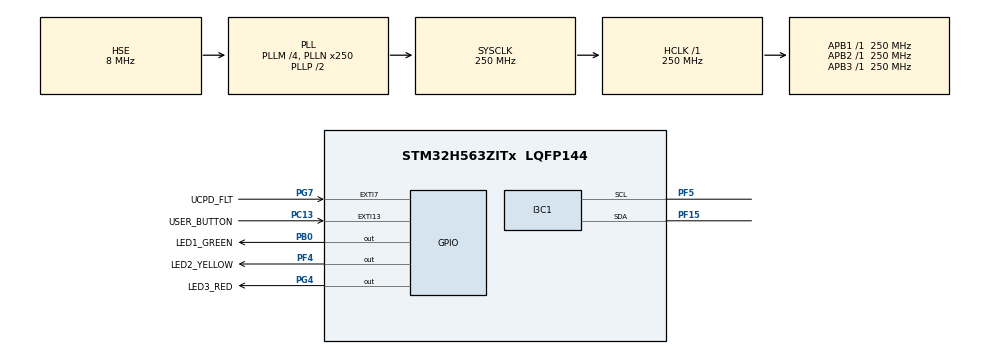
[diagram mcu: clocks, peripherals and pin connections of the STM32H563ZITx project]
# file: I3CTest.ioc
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CORTEX_M33_NS.userName=CORTEX_M33
I3C1.BusFreeDuration=1050
I3C1.BusUsage=MixedUsage
I3C1.DutyCycleI3C=50
I3C1.Register0=0x4aae0909
I3C1.Register1=0x108300f8
I3C1.SCLI2CHighDuration=0x4a
I3C1.SCLI3CHighDuration=0x09
I3C1.SCLODLowDuration=0xae
I3C1.SCLPPLowDuration=0x09
I3C1.SDAHoldTime=HAL_I3C_SDA_HOLD_TIME_1_5
I3C1.hexBusFreeDuration=0x83
I3C1.hexBusIdleDuration=0xf8
Mcu.Family=STM32H5
Mcu.Name=STM32H563ZITx
Mcu.Package=LQFP144
NVIC.PriorityGroup=NVIC_PRIORITYGROUP_4
PA1.GPIO_Label=RMII_REF_CLK
PA1.GPIO_Mode=GPIO_MODE_AF_PP
PA1.GPIO_PuPd=GPIO_NOPULL
PA1.GPIO_Speed=GPIO_SPEED_FREQ_LOW
PA1.Signal=ETH_REF_CLK
PA11.GPIO_Label=USB_FS_N
PA11.Signal=USB_DM
PA12.GPIO_Label=USB_FS_P
PA12.Signal=USB_DP
PA13(JTMS/SWDIO).GPIO_Label=SWDIO
PA13(JTMS/SWDIO).Signal=DEBUG_JTMS-SWDIO
PA14(JTCK/SWCLK).GPIO_Label=SWCLK
PA14(JTCK/SWCLK).Signal=DEBUG_JTCK-SWCLK
PA15(JTDI).GPIO_Label=T_JTDI
PA15(JTDI).Signal=DEBUG_JTDI
PA2.GPIO_Label=RMII_MDIO
PA2.GPIO_Mode=GPIO_MODE_AF_PP
PA2.GPIO_PuPd=GPIO_NOPULL
PA2.GPIO_Speed=GPIO_SPEED_FREQ_LOW
PA2.Signal=ETH_MDIO
PA4.GPIO_Label=VBUS_SENSE
PA4.Signal=ADCx_INP18
PA7.GPIO_Label=RMII_CRS_DV
PA7.GPIO_Mode=GPIO_MODE_AF_PP
PA7.GPIO_PuPd=GPIO_NOPULL
PA7.GPIO_Speed=GPIO_SPEED_FREQ_LOW
PA7.Signal=ETH_CRS_DV
PA9.GPIO_Label=UCDP_DBn
PA9.Signal=UCPD1_DB1
PB0.GPIO_Label=LED1_GREEN
PB0.Signal=GPIO_Output
PB13.GPIO_Label=UCPD_CC1
PB13.Signal=UCPD1_CC1
PB14.GPIO_Label=UCPD_CC2
PB14.Signal=UCPD1_CC2
PB15.GPIO_Label=RMII_TXD1
PB15.GPIO_Mode=GPIO_MODE_AF_PP
PB15.GPIO_PuPd=GPIO_NOPULL
PB15.GPIO_Speed=GPIO_SPEED_FREQ_LOW
PB15.Signal=ETH_TXD1
PB3(JTDO/TRACESWO).GPIO_Label=SWO
PB3(JTDO/TRACESWO).Signal=DEBUG_JTDO-SWO
PB6.GPIO_Label=ARD_D1_TX
PB6.Signal=LPUART1_TX
PB7.GPIO_Label=ARD_D0_RX
PB7.Signal=LPUART1_RX
PC1.GPIO_Label=RMII_MDC
PC1.GPIO_Mode=GPIO_MODE_AF_PP
PC1.GPIO_PuPd=GPIO_NOPULL
PC1.GPIO_Speed=GPIO_SPEED_FREQ_LOW
PC1.Signal=ETH_MDC
PC13.GPIO_Label=USER_BUTTON
PC13.Signal=GPXTI13
PC14-OSC32_IN(OSC32_IN).Mode=LSE-External-Oscillator
PC14-OSC32_IN(OSC32_IN).Signal=RCC_OSC32_IN
PC15-OSC32_OUT(OSC32_OUT).Mode=LSE-External-Oscillator
PC15-OSC32_OUT(OSC32_OUT).Signal=RCC_OSC32_OUT
PC4.GPIO_Label=RMII_RXD0
PC4.GPIO_Mode=GPIO_MODE_AF_PP
PC4.GPIO_PuPd=GPIO_NOPULL
PC4.GPIO_Speed=GPIO_SPEED_FREQ_LOW
PC4.Signal=ETH_RXD0
PC5.GPIO_Label=RMII_RXD1
PC5.GPIO_Mode=GPIO_MODE_AF_PP
PC5.GPIO_PuPd=GPIO_NOPULL
PC5.GPIO_Speed=GPIO_SPEED_FREQ_LOW
PC5.Signal=ETH_RXD1
PD8.GPIO_Label=T_VCP_TX
PD8.Signal=USART3_TX
PD9.GPIO_Label=T_VCP_RX
PD9.Signal=USART3_RX
PE2.GPIO_Label=TRACE_CK
PE2.Signal=DEBUG_TRACECLK
PE3.GPIO_Label=TRACE_D0
PE3.Signal=DEBUG_TRACED0
PE4.GPIO_Label=TRACE_D1
PE4.Signal=DEBUG_TRACED1
PE5.GPIO_Label=TRACE_D2
PE5.Signal=DEBUG_TRACED2
PE6.GPIO_Label=TRACE_D3
PE6.Signal=DEBUG_TRACED3
PF15.Mode=Controller
PF15.Signal=I3C1_SDA
PF4.GPIO_Label=LED2_YELLOW
PF4.Signal=GPIO_Output
PF5.Mode=Controller
PF5.Signal=I3C1_SCL
PG11.GPIO_Label=RMII_TXT_EN
PG11.GPIO_Mode=GPIO_MODE_AF_PP
PG11.GPIO_PuPd=GPIO_NOPULL
PG11.GPIO_Speed=GPIO_SPEED_FREQ_LOW
PG11.Signal=ETH_TX_EN
PG13.GPIO_Label=RMI_TXD0
PG13.GPIO_Mode=GPIO_MODE_AF_PP
PG13.GPIO_PuPd=GPIO_NOPULL
PG13.GPIO_Speed=GPIO_SPEED_FREQ_LOW
PG13.Signal=ETH_TXD0
PG4.GPIO_Label=LED3_RED
PG4.Signal=GPIO_Output
PG7.GPIO_Label=UCPD_FLT
PG7.Signal=GPXTI7
PH0-OSC_IN(PH0).GPIO_Label=STLK_MCO
PH0-OSC_IN(PH0).Mode=HSE-DIG-External-Clock-Source
PH0-OSC_IN(PH0).Signal=RCC_OSC_IN
ProjectManager.HeapSize=0x200
ProjectManager.StackSize=0x400
ProjectManager.TargetToolchain=STM32CubeIDE
RCC.ADCFreq_Value=250000000
RCC.AHBFreq_Value=250000000
RCC.APB1Freq_Value=250000000
RCC.APB1TimFreq_Value=250000000
RCC.APB2Freq_Value=250000000
RCC.APB2TimFreq_Value=250000000
RCC.APB3Freq_Value=250000000
RCC.CSI_VALUE=4000000
RCC.CortexFreq_Value=250000000
RCC.EPOD_VALUE=8000000
RCC.HCLKFreq_Value=250000000
RCC.HSE_VALUE=8000000
RCC.HSI48_VALUE=48000000
RCC.HSIDiv=RCC_HSI_DIV1
RCC.HSI_VALUE=64000000
RCC.LSIRC_VALUE=32000
RCC.PLLM=4
RCC.PLLN=250
RCC.PLLSourceVirtual=RCC_PLL1_SOURCE_HSE
RCC.SYSCLKFreq_VALUE=250000000
RCC.SYSCLKSource=RCC_SYSCLKSOURCE_PLLCLK
RCC.USBFreq_Value=48000000
RCC.VCOOutputFreq_Value=500000000
SH.ADCx_INP18.0=ADC1_INP18
VP_ICACHE_VS_ICACHE.Mode=DirectMappedCache
VP_PWR_VS_SECSignals.Mode=Security/Privilege
board=NUCLEO-H563ZI

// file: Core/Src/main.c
/* USER CODE BEGIN Header */
/**
 ******************************************************************************
 * @file           : main.c
 * @brief          : Main program body
 ******************************************************************************
 * @attention
 *
 * Copyright (c) 2023 STMicroelectronics.
 * All rights reserved.
 *
 * This software is licensed under terms that can be found in the LICENSE file
 * in the root directory of this software component.
 * If no LICENSE file comes with this software, it is provided AS-IS.
 *
 ******************************************************************************
 */
/* USER CODE END Header */
#include "main.h"

/* USER CODE BEGIN Includes */
#include "bmi3.h"
#include "bmi323.h"
#include "common.h"
#include <stdio.h>
#include <math.h>
#include "i3c_handle.h"

/* USER CODE END Includes */

/* USER CODE BEGIN PD */
/*! Earth's gravity in m/s^2 */
#define GRAVITY_EARTH (9.80665f)

#define ACCEL UINT8_C(0x00)
#define GYRO UINT8_C(0x01)
#define TEMPERATURE UINT8_C(0x02)
/* USER CODE END PD */

I3C_HandleTypeDef hi3c1;

/* USER CODE BEGIN PV */
/******************************************************************************/
/*!         Structure Definition                                              */

/*! Structure to define accelerometer and gyroscope configuration. */
struct bmi3_sens_config config[2];

/******************************************************************************/
/*!         Static Function Declaration                                       */

/*!
 *  @brief This internal API is used to set configurations for FIFO, accelerometer and gyroscope.
 *
 *  @param[in] dev       : Structure instance of bmi3_dev.
 *
 *  @return Status of execution.
 */
static int8_t set_sensor_config(struct bmi3_dev *dev);

/*!
 *  @brief This internal function converts lsb to meter per second squared for 16 bit accelerometer for
 *  range 2G, 4G, 8G or 16G.
 *
 *  @param[in] val       : LSB from each axis.
 *  @param[in] g_range   : Gravity range.
 *  @param[in] bit_width : Resolution for accel.
 *
 *  @return Accel values in meter per second squared.
 */
static float lsb_to_mps2(int16_t val, int8_t g_range, uint8_t bit_width);

/*!
 *  @brief This function converts lsb to degree per second for 16 bit gyro at
 *  range 125, 250, 500, 1000 or 2000dps.
 *
 *  @param[in] val       : LSB from each axis.
 *  @param[in] dps       : Degree per second.
 *  @param[in] bit_width : Resolution for gyro.
 *
 *  @return Degree per second.
 */
static float lsb_to_dps(int16_t val, float dps, uint8_t bit_width);
/* USER CODE END PV */

void SystemClock_Config(void);
static void MX_GPIO_Init(void);
static void MX_I3C1_Init(void);
static void MX_ICACHE_Init(void);

int main(void)
{

  /* MCU Configuration--------------------------------------------------------*/

  /* Reset of all peripherals, Initializes the Flash interface and the Systick. */
  HAL_Init();

  /* Configure the system clock */
  SystemClock_Config();

  /* Initialize all configured peripherals */
  MX_GPIO_Init();
  MX_I3C1_Init();
  MX_ICACHE_Init();

  /* Infinite loop */
  /* USER CODE BEGIN WHILE */
  struct bmi3_dev dev;
  int8_t rslt;

  /* Variable to set the data sample rate of i3c sync
   * 0x0032 is set to 50 samples this value can vary  */
  uint16_t sample_rate = 0x0032;

  /* Variable to set the delay time of i3c sync */
  uint8_t delay_time = BMI3_I3C_SYNC_DIVISION_FACTOR_11;

  /* Variable to set the i3c sync ODR */
  uint8_t odr = BMI3_I3C_SYNC_ODR_50HZ;

  /* Variable to enable the filer */
  uint8_t i3c_tc_res = BMI323_ENABLE;

  uint8_t limit = 20;

  uint16_t int_status;

  struct bmi3_feature_enable feature = {0};

  struct bmi3_sensor_data sensor_data[3];

  /* Variable to store temperature */
  float temperature_value;

  float acc_x = 0, acc_y = 0, acc_z = 0;
  float gyr_x = 0, gyr_y = 0, gyr_z = 0;
  uint8_t indx = 0;

  /* Function to select interface between SPI and I2C, according to that the device structure gets updated.
   * Interface reference is given as a parameter
   * For I2C : BMI3_I2C_INTF
   * For SPI : BMI3_SPI_INTF
   */
  rslt = bmi3_interface_init(&dev, BMI3_I3C_INTF);
  bmi3_error_codes_print_result("bmi3_interface_init", rslt);

  if (rslt == BMI323_OK)
  {
    /* Initialize BMI323 */
    rslt = bmi323_init(&dev);
    bmi3_error_codes_print_result("bmi323_init", rslt);

    if (rslt == BMI323_OK)
    {
      rslt = bmi323_configure_enhanced_flexibility(&dev);
      bmi3_error_codes_print_result("bmi323_configure_enhanced_flexibility", rslt);

      if (rslt == BMI323_OK)
      {
        rslt = set_sensor_config(&dev);
        bmi3_error_codes_print_result("set_sensor_config", rslt);

        /* Enable i3c_sync feature */
        feature.i3c_sync_en = BMI323_ENABLE;

        /* Enable the selected sensors */
        rslt = bmi323_select_sensor(&feature, &dev);
        bmi3_error_codes_print_result("bmi323_select_sensor", rslt);

        /* Set the data sample rate of i3c sync */
        rslt = bmi323_set_i3c_tc_sync_tph(sample_rate, &dev);
        bmi3_error_codes_print_result("set_i3c_tc_sync_tph", rslt);

        /* Set the delay time of i3c sync */
        rslt = bmi323_set_i3c_tc_sync_tu(delay_time, &dev);
        bmi3_error_codes_print_result("set_i3c_tc_sync_tu", rslt);

        /* Set i3c sync ODR */
        rslt = bmi323_set_i3c_tc_sync_odr(odr, &dev);
        bmi3_error_codes_print_result("set_i3c_tc_sync_odr", rslt);

        /* Enable the i3c sync filter */
        rslt = bmi323_set_i3c_sync_i3c_tc_res(i3c_tc_res, &dev);
        bmi3_error_codes_print_result("set_i3c_sync_i3c_tc_res", rslt);

        /* After any change to the I3C-Sync configuration parameters,
         * a config changed CMD (0x0201) must be written
         * to CMD register to update the internal configuration */
        rslt = bmi323_set_command_register(BMI3_CMD_I3C_TCSYNC_UPDATE, &dev);
        bmi3_error_codes_print_result("bmi323_set_command_register", rslt);

        /* Set the type of sensor data */
        sensor_data[ACCEL].type = BMI3_I3C_SYNC_ACCEL;
        sensor_data[GYRO].type = BMI3_I3C_SYNC_GYRO;
        sensor_data[TEMPERATURE].type = BMI3_I3C_SYNC_TEMP;

        printf("I3C accel, gyro and temperature data\n");

        printf(
            "\nDATA_SET, i3c_acc_x, i3c_acc_y, i3c_acc_z, i3c_time, Gravity-x, Gravity-y, Gravity-z, i3c_gyro_x, i3c_gyro_y, i3c_gyro_z, DPS-x, DPS-y, DPS-z, i3c_temperature, i3c_sync_time, Temperature data(Degree Celcius)\n");

        while (indx <= limit)
        {
          /* Delay provided based on i3c sync ODR */
          dev.delay_us(20000, dev.intf_ptr);

          /* To get the status of i3c sync interrupt status. */
          rslt = bmi323_get_int1_status(&int_status, &dev);
          bmi3_error_codes_print_result("bmi323_get_int1_status", rslt);

          /* To check the i3c sync accel data */
          if (int_status & BMI3_INT_STATUS_I3C)
          {
            rslt = bmi323_get_sensor_data(sensor_data, 3, &dev);
            bmi3_error_codes_print_result("bmi323_get_sensor_data", rslt);

            /* Converting lsb to meter per second squared for 16 bit accelerometer at 2G range. */
            acc_x = lsb_to_mps2((int16_t)sensor_data[ACCEL].sens_data.i3c_sync.sync_x, 2, dev.resolution);
            acc_y = lsb_to_mps2((int16_t)sensor_data[ACCEL].sens_data.i3c_sync.sync_y, 2, dev.resolution);
            acc_z = lsb_to_mps2((int16_t)sensor_data[ACCEL].sens_data.i3c_sync.sync_z, 2, dev.resolution);

            /* Converting lsb to degree per second for 16 bit gyro at 2000dps range. */
            gyr_x = lsb_to_dps((int16_t)sensor_data[GYRO].sens_data.i3c_sync.sync_x,
                               (float)2000,
                               dev.resolution);
            gyr_y = lsb_to_dps((int16_t)sensor_data[GYRO].sens_data.i3c_sync.sync_y,
                               (float)2000,
                               dev.resolution);
            gyr_z = lsb_to_dps((int16_t)sensor_data[GYRO].sens_data.i3c_sync.sync_z,
                               (float)2000,
                               dev.resolution);

            temperature_value =
                (float)((((float)((int16_t)sensor_data[TEMPERATURE].sens_data.i3c_sync.sync_temp)) /
                         512.0) +
                        23.0);

            printf(
                "%d, %d, %d, %d, %d, %4.2f, %4.2f, %4.2f, %d, %d, %d, %d, %4.2f, %4.2f, %4.2f, %d, %d, %f\t\n",
                indx,
                sensor_data[ACCEL].sens_data.i3c_sync.sync_x,
                sensor_data[ACCEL].sens_data.i3c_sync.sync_y,
                sensor_data[ACCEL].sens_data.i3c_sync.sync_z,
                sensor_data[ACCEL].sens_data.i3c_sync.sync_time,
                acc_x,
                acc_y,
                acc_z,
                sensor_data[GYRO].sens_data.i3c_sync.sync_x,
                sensor_data[GYRO].sens_data.i3c_sync.sync_y,
                sensor_data[GYRO].sens_data.i3c_sync.sync_z,
                sensor_data[GYRO].sens_data.i3c_sync.sync_time,
                gyr_x,
                gyr_y,
                gyr_z,
                sensor_data[TEMPERATURE].sens_data.i3c_sync.sync_temp,
                sensor_data[TEMPERATURE].sens_data.i3c_sync.sync_time,
                temperature_value);
          }

          indx++;
        }
      }
    }
  }

  // bmi3_coines_deinit();

  return rslt;
}

/*!
 * @brief This internal API is used to set configurations for accelerometer, gyroscope and FIFO.
 */
static int8_t set_sensor_config(struct bmi3_dev *dev)
{
  int8_t rslt;

  /* Structure to define interrupt with its feature */
  struct bmi3_map_int map_int = {0};

  /* Configure type of feature */
  config[ACCEL].type = BMI323_ACCEL;
  config[GYRO].type = BMI323_GYRO;

  /* Get default configurations for the type of feature selected */
  rslt = bmi323_get_sensor_config(config, 2, dev);
  bmi3_error_codes_print_result("bmi323_get_sensor_config", rslt);

  /* Configure the accel and gyro settings */
  config[ACCEL].cfg.acc.bwp = BMI3_ACC_BW_ODR_QUARTER;
  config[ACCEL].cfg.acc.range = BMI3_ACC_RANGE_2G;
  config[ACCEL].cfg.acc.acc_mode = BMI3_ACC_MODE_NORMAL;

  config[GYRO].cfg.gyr.bwp = BMI3_GYR_BW_ODR_HALF;
  config[GYRO].cfg.gyr.range = BMI3_GYR_RANGE_125DPS;
  config[GYRO].cfg.gyr.gyr_mode = BMI3_GYR_MODE_NORMAL;

  rslt = bmi323_set_sensor_config(config, 2, dev);
  bmi3_error_codes_print_result("bmi323_set_sensor_config", rslt);

  /* Get configurations for the type of feature selected */
  rslt = bmi323_get_sensor_config(config, 2, dev);
  bmi3_error_codes_print_result("bmi323_get_sensor_config", rslt);

  /* Select the feature and map the interrupt to pin BMI3_INT1 or BMI3_INT2 */
  map_int.i3c_out = BMI3_INT1;

  /* Map i3c sync interrupt to interrupt pin. */
  rslt = bmi323_map_interrupt(map_int, dev);
  bmi3_error_codes_print_result("bmi323_map_interrupt", rslt);

  return rslt;
}

/*!
 * @brief This function converts lsb to meter per second squared for 16 bit accelerometer at
 * range 2G, 4G, 8G or 16G.
 */
static float lsb_to_mps2(int16_t val, int8_t g_range, uint8_t bit_width)
{
  double power = 2;

  float half_scale = (float)((pow((double)power, (double)bit_width) / 2.0f));

  return (GRAVITY_EARTH * val * g_range) / half_scale;
}

/*!
 * @brief This function converts lsb to degree per second for 16 bit gyro at
 * range 125, 250, 500, 1000 or 2000dps.
 */
static float lsb_to_dps(int16_t val, float dps, uint8_t bit_width)
{
  double power = 2;

  float half_scale = (float)((pow((double)power, (double)bit_width) / 2.0f));

  return (dps / (half_scale)) * (val);
}

void SystemClock_Config(void)
{
  RCC_OscInitTypeDef RCC_OscInitStruct = {0};
  RCC_ClkInitTypeDef RCC_ClkInitStruct = {0};

  /** Configure the main internal regulator output voltage
   */
  __HAL_PWR_VOLTAGESCALING_CONFIG(PWR_REGULATOR_VOLTAGE_SCALE0);

  while (!__HAL_PWR_GET_FLAG(PWR_FLAG_VOSRDY))
  {
  }

  /** Initializes the RCC Oscillators according to the specified parameters
   * in the RCC_OscInitTypeDef structure.
   */
  RCC_OscInitStruct.OscillatorType = RCC_OSCILLATORTYPE_HSE;
  RCC_OscInitStruct.HSEState = RCC_HSE_BYPASS_DIGITAL;
  RCC_OscInitStruct.PLL.PLLState = RCC_PLL_ON;
  RCC_OscInitStruct.PLL.PLLSource = RCC_PLL1_SOURCE_HSE;
  RCC_OscInitStruct.PLL.PLLM = 4;
  RCC_OscInitStruct.PLL.PLLN = 250;
  RCC_OscInitStruct.PLL.PLLP = 2;
  RCC_OscInitStruct.PLL.PLLQ = 2;
  RCC_OscInitStruct.PLL.PLLR = 2;
  RCC_OscInitStruct.PLL.PLLRGE = RCC_PLL1_VCIRANGE_1;
  RCC_OscInitStruct.PLL.PLLVCOSEL = RCC_PLL1_VCORANGE_WIDE;
  RCC_OscInitStruct.PLL.PLLFRACN = 0;
  if (HAL_RCC_OscConfig(&RCC_OscInitStruct) != HAL_OK)
  {
    Error_Handler();
  }

  /** Initializes the CPU, AHB and APB buses clocks
   */
  RCC_ClkInitStruct.ClockType = RCC_CLOCKTYPE_HCLK | RCC_CLOCKTYPE_SYSCLK | RCC_CLOCKTYPE_PCLK1 | RCC_CLOCKTYPE_PCLK2 | RCC_CLOCKTYPE_PCLK3;
  RCC_ClkInitStruct.SYSCLKSource = RCC_SYSCLKSOURCE_PLLCLK;
  RCC_ClkInitStruct.AHBCLKDivider = RCC_SYSCLK_DIV1;
  RCC_ClkInitStruct.APB1CLKDivider = RCC_HCLK_DIV1;
  RCC_ClkInitStruct.APB2CLKDivider = RCC_HCLK_DIV1;
  RCC_ClkInitStruct.APB3CLKDivider = RCC_HCLK_DIV1;

  if (HAL_RCC_ClockConfig(&RCC_ClkInitStruct, FLASH_LATENCY_5) != HAL_OK)
  {
    Error_Handler();
  }
}

static void MX_I3C1_Init(void)
{

  I3C_FifoConfTypeDef sFifoConfig = {0};
  I3C_CtrlConfTypeDef sCtrlConfig = {0};

  hi3c1.Instance = I3C1;
  hi3c1.Mode = HAL_I3C_MODE_CONTROLLER;
  hi3c1.Init.CtrlBusCharacteristic.SDAHoldTime = HAL_I3C_SDA_HOLD_TIME_1_5;
  hi3c1.Init.CtrlBusCharacteristic.WaitTime = HAL_I3C_OWN_ACTIVITY_STATE_0;
  hi3c1.Init.CtrlBusCharacteristic.SCLPPLowDuration = 0x09;
  hi3c1.Init.CtrlBusCharacteristic.SCLI3CHighDuration = 0x09;
  hi3c1.Init.CtrlBusCharacteristic.SCLODLowDuration = 0xae;
  hi3c1.Init.CtrlBusCharacteristic.SCLI2CHighDuration = 0x4a;
  hi3c1.Init.CtrlBusCharacteristic.BusFreeDuration = 0x83;
  hi3c1.Init.CtrlBusCharacteristic.BusIdleDuration = 0xf8;
  if (HAL_I3C_Init(&hi3c1) != HAL_OK)
  {
    Error_Handler();
  }

  /** Configure FIFO
   */
  sFifoConfig.RxFifoThreshold = HAL_I3C_RXFIFO_THRESHOLD_1_4;
  sFifoConfig.TxFifoThreshold = HAL_I3C_TXFIFO_THRESHOLD_1_4;
  sFifoConfig.ControlFifo = HAL_I3C_CONTROLFIFO_DISABLE;
  sFifoConfig.StatusFifo = HAL_I3C_STATUSFIFO_DISABLE;
  if (HAL_I3C_SetConfigFifo(&hi3c1, &sFifoConfig) != HAL_OK)
  {
    Error_Handler();
  }

  /** Configure controller
   */
  sCtrlConfig.DynamicAddr = 0;
  sCtrlConfig.StallTime = 0x00;
  sCtrlConfig.HotJoinAllowed = DISABLE;
  sCtrlConfig.ACKStallState = DISABLE;
  sCtrlConfig.CCCStallState = DISABLE;
  sCtrlConfig.TxStallState = DISABLE;
  sCtrlConfig.RxStallState = DISABLE;
  sCtrlConfig.HighKeeperSDA = DISABLE;
  if (HAL_I3C_Ctrl_Config(&hi3c1, &sCtrlConfig) != HAL_OK)
  {
    Error_Handler();
  }
}

static void MX_ICACHE_Init(void)
{

  /** Enable instruction cache in 1-way (direct mapped cache)
   */
  if (HAL_ICACHE_ConfigAssociativityMode(ICACHE_1WAY) != HAL_OK)
  {
    Error_Handler();
  }
  if (HAL_ICACHE_Enable() != HAL_OK)
  {
    Error_Handler();
  }
}

static void MX_GPIO_Init(void)
{
  GPIO_InitTypeDef GPIO_InitStruct = {0};

  /* GPIO Ports Clock Enable */
  __HAL_RCC_GPIOE_CLK_ENABLE();
  __HAL_RCC_GPIOC_CLK_ENABLE();
  __HAL_RCC_GPIOF_CLK_ENABLE();
  __HAL_RCC_GPIOH_CLK_ENABLE();
  __HAL_RCC_GPIOA_CLK_ENABLE();
  __HAL_RCC_GPIOB_CLK_ENABLE();
  __HAL_RCC_GPIOD_CLK_ENABLE();
  __HAL_RCC_GPIOG_CLK_ENABLE();

  /*Configure GPIO pin Output Level */
  HAL_GPIO_WritePin(LED2_YELLOW_GPIO_Port, LED2_YELLOW_Pin, GPIO_PIN_RESET);

  /*Configure GPIO pin Output Level */
  HAL_GPIO_WritePin(LED1_GREEN_GPIO_Port, LED1_GREEN_Pin, GPIO_PIN_RESET);

  /*Configure GPIO pin Output Level */
  HAL_GPIO_WritePin(LED3_RED_GPIO_Port, LED3_RED_Pin, GPIO_PIN_RESET);

  /*Configure GPIO pin : USER_BUTTON_Pin */
  GPIO_InitStruct.Pin = USER_BUTTON_Pin;
  GPIO_InitStruct.Mode = GPIO_MODE_IT_RISING;
  GPIO_InitStruct.Pull = GPIO_NOPULL;
  HAL_GPIO_Init(USER_BUTTON_GPIO_Port, &GPIO_InitStruct);

  /*Configure GPIO pin : LED2_YELLOW_Pin */
  GPIO_InitStruct.Pin = LED2_YELLOW_Pin;
  GPIO_InitStruct.Mode = GPIO_MODE_OUTPUT_PP;
  GPIO_InitStruct.Pull = GPIO_NOPULL;
  GPIO_InitStruct.Speed = GPIO_SPEED_FREQ_LOW;
  HAL_GPIO_Init(LED2_YELLOW_GPIO_Port, &GPIO_InitStruct);

  /*Configure GPIO pins : RMII_MDC_Pin RMII_RXD0_Pin RMII_RXD1_Pin */
  GPIO_InitStruct.Pin = RMII_MDC_Pin | RMII_RXD0_Pin | RMII_RXD1_Pin;
  GPIO_InitStruct.Mode = GPIO_MODE_AF_PP;
  GPIO_InitStruct.Pull = GPIO_NOPULL;
  GPIO_InitStruct.Speed = GPIO_SPEED_FREQ_LOW;
  GPIO_InitStruct.Alternate = GPIO_AF11_ETH;
  HAL_GPIO_Init(GPIOC, &GPIO_InitStruct);

  /*Configure GPIO pins : RMII_REF_CLK_Pin RMII_MDIO_Pin RMII_CRS_DV_Pin */
  GPIO_InitStruct.Pin = RMII_REF_CLK_Pin | RMII_MDIO_Pin | RMII_CRS_DV_Pin;
  GPIO_InitStruct.Mode = GPIO_MODE_AF_PP;
  GPIO_InitStruct.Pull = GPIO_NOPULL;
  GPIO_InitStruct.Speed = GPIO_SPEED_FREQ_LOW;
  GPIO_InitStruct.Alternate = GPIO_AF11_ETH;
  HAL_GPIO_Init(GPIOA, &GPIO_InitStruct);

  /*Configure GPIO pin : VBUS_SENSE_Pin */
  GPIO_InitStruct.Pin = VBUS_SENSE_Pin;
  GPIO_InitStruct.Mode = GPIO_MODE_ANALOG;
  GPIO_InitStruct.Pull = GPIO_NOPULL;
  HAL_GPIO_Init(VBUS_SENSE_GPIO_Port, &GPIO_InitStruct);

  /*Configure GPIO pin : LED1_GREEN_Pin */
  GPIO_InitStruct.Pin = LED1_GREEN_Pin;
  GPIO_InitStruct.Mode = GPIO_MODE_OUTPUT_PP;
  GPIO_InitStruct.Pull = GPIO_NOPULL;
  GPIO_InitStruct.Speed = GPIO_SPEED_FREQ_LOW;
  HAL_GPIO_Init(LED1_GREEN_GPIO_Port, &GPIO_InitStruct);

  /*Configure GPIO pins : UCPD_CC1_Pin UCPD_CC2_Pin */
  GPIO_InitStruct.Pin = UCPD_CC1_Pin | UCPD_CC2_Pin;
  GPIO_InitStruct.Mode = GPIO_MODE_ANALOG;
  GPIO_InitStruct.Pull = GPIO_NOPULL;
  HAL_GPIO_Init(GPIOB, &GPIO_InitStruct);

  /*Configure GPIO pin : RMII_TXD1_Pin */
  GPIO_InitStruct.Pin = RMII_TXD1_Pin;
  GPIO_InitStruct.Mode = GPIO_MODE_AF_PP;
  GPIO_InitStruct.Pull = GPIO_NOPULL;
  GPIO_InitStruct.Speed = GPIO_SPEED_FREQ_LOW;
  GPIO_InitStruct.Alternate = GPIO_AF11_ETH;
  HAL_GPIO_Init(RMII_TXD1_GPIO_Port, &GPIO_InitStruct);

  /*Configure GPIO pins : T_VCP_TX_Pin T_VCP_RX_Pin */
  GPIO_InitStruct.Pin = T_VCP_TX_Pin | T_VCP_RX_Pin;
  GPIO_InitStruct.Mode = GPIO_MODE_AF_PP;
  GPIO_InitStruct.Pull = GPIO_NOPULL;
  GPIO_InitStruct.Speed = GPIO_SPEED_FREQ_LOW;
  GPIO_InitStruct.Alternate = GPIO_AF7_USART3;
  HAL_GPIO_Init(GPIOD, &GPIO_InitStruct);

  /*Configure GPIO pin : LED3_RED_Pin */
  GPIO_InitStruct.Pin = LED3_RED_Pin;
  GPIO_InitStruct.Mode = GPIO_MODE_OUTPUT_PP;
  GPIO_InitStruct.Pull = GPIO_NOPULL;
  GPIO_InitStruct.Speed = GPIO_SPEED_FREQ_LOW;
  HAL_GPIO_Init(LED3_RED_GPIO_Port, &GPIO_InitStruct);

  /*Configure GPIO pin : UCPD_FLT_Pin */
  GPIO_InitStruct.Pin = UCPD_FLT_Pin;
  GPIO_InitStruct.Mode = GPIO_MODE_IT_RISING;
  GPIO_InitStruct.Pull = GPIO_NOPULL;
  HAL_GPIO_Init(UCPD_FLT_GPIO_Port, &GPIO_InitStruct);

  /*Configure GPIO pins : USB_FS_N_Pin USB_FS_P_Pin */
  GPIO_InitStruct.Pin = USB_FS_N_Pin | USB_FS_P_Pin;
  GPIO_InitStruct.Mode = GPIO_MODE_AF_PP;
  GPIO_InitStruct.Pull = GPIO_NOPULL;
  GPIO_InitStruct.Speed = GPIO_SPEED_FREQ_LOW;
  GPIO_InitStruct.Alternate = GPIO_AF10_USB;
  HAL_GPIO_Init(GPIOA, &GPIO_InitStruct);

  /*Configure GPIO pins : RMII_TXT_EN_Pin RMI_TXD0_Pin */
  GPIO_InitStruct.Pin = RMII_TXT_EN_Pin | RMI_TXD0_Pin;
  GPIO_InitStruct.Mode = GPIO_MODE_AF_PP;
  GPIO_InitStruct.Pull = GPIO_NOPULL;
  GPIO_InitStruct.Speed = GPIO_SPEED_FREQ_LOW;
  GPIO_InitStruct.Alternate = GPIO_AF11_ETH;
  HAL_GPIO_Init(GPIOG, &GPIO_InitStruct);

  /*Configure GPIO pins : ARD_D1_TX_Pin ARD_D0_RX_Pin */
  GPIO_InitStruct.Pin = ARD_D1_TX_Pin | ARD_D0_RX_Pin;
  GPIO_InitStruct.Mode = GPIO_MODE_AF_PP;
  GPIO_InitStruct.Pull = GPIO_NOPULL;
  GPIO_InitStruct.Speed = GPIO_SPEED_FREQ_LOW;
  GPIO_InitStruct.Alternate = GPIO_AF8_LPUART1;
  HAL_GPIO_Init(GPIOB, &GPIO_InitStruct);

}

/* USER CODE BEGIN 4 */

/* USER CODE BEGIN 4 */

/* USER CODE END 4 */

void Error_Handler(void)
{
  __disable_irq();
  while (1)
  {
  }
}
